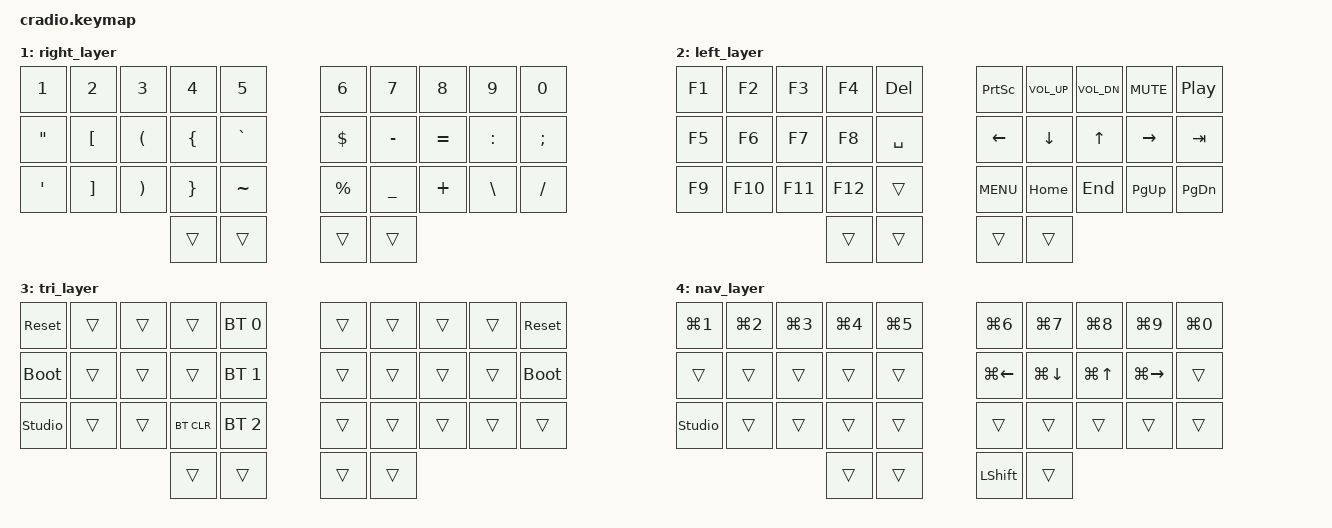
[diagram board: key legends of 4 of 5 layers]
// Copyright (c) 2022 The ZMK Contributors
// SPDX-License-Identifier: MIT

#include <behaviors.dtsi>
#include <dt-bindings/zmk/keys.h>
#include <dt-bindings/zmk/bt.h>

// Home row mods macro
#define HRML(k1,k2,k3,k4) &ht LGUI k1  &ht LALT k2  &ht LSHFT k3  &ht LCTRL k4
#define HRMR(k1,k2,k3,k4) &ht RCTRL k1  &ht RSHFT k2  &ht RALT k3  &ht RGUI k4

/ {
    behaviors {
        ht: hold_tap {
            compatible = "zmk,behavior-hold-tap";
            #binding-cells = <2>;
            flavor = "tap-preferred";
            tapping-term-ms = <220>;
            quick-tap-ms = <150>;
            require-prior-idle-ms = <100>;
            bindings = <&kp>, <&kp>;
        };
    };

    conditional_layers {
        compatible = "zmk,conditional-layers";
        tri_layer {
            if-layers = <1 2>;
            then-layer = <3>;
        };
    };

    keymap {
        compatible = "zmk,keymap";
        default_layer {
            bindings = <
        //╭──────────┬──────────┬──────────┬──────────┬──────────╮   ╭──────────┬──────────┬──────────┬──────────┬──────────╮
        //│  Q       │  W       │  E       │  R       │  T       │   │  Y       │  U       │  I       │  O       │  P       │
            &kp Q      &kp W      &kp E      &kp R      &kp T          &kp Y      &kp U      &kp I      &kp O      &kp P
        //├──────────┼──────────┼──────────┼──────────┼──────────┤   ├──────────┼──────────┼──────────┼──────────┼──────────┤
        //│  A       │  S       │  D       │  F       │  G       │   │  H       │  J       │  K       │  L       │ :        │
            HRML(A,        S,         D,         F)     &kp G          &kp H      HRMR(J,        K,         L,        SEMI)
        //├──────────┼──────────┼──────────┼──────────┼──────────┤   ├──────────┼──────────┼──────────┼──────────┼──────────┤
        //│  Z       │  X       │  C       │  V       │  B       │   │  N       │  M       │ , <      │ . >      │ / ?      │
            &kp Z      &kp X      &kp C      &kp V      &kp B          &kp N      &kp M      &kp COMMA  &kp DOT    &kp FSLH
        //╰──────────┴──────────┴──────────┼──────────┼──────────┤   ├──────────┼──────────┼──────────┴──────────┴──────────╯
                                           &lt 1 SPACE   &lt 4 ENTER   &lt 2 ESC  &lt 1 BSPC
        //                                 ╰──────────┴──────────╯   ╰──────────┴──────────╯
            >;
        };

        right_layer {
            bindings = <
        //╭──────────┬──────────┬──────────┬──────────┬──────────╮   ╭──────────┬──────────┬──────────┬──────────┬──────────╮
        //│ 1        │  2       │  3       │  4       │  5       │   │ 6        │ 7        │ 8        │ 9        │  0       │
            &kp N1     &kp N2     &kp N3     &kp N4     &kp N5         &kp N6     &kp N7      &kp N8    &kp N9     &kp N0
        //├──────────┼──────────┼──────────┼──────────┼──────────┤   ├──────────┼──────────┼──────────┼──────────┼──────────┤
        //│ "        │  [       │  (       │  {       │  `       │   │ $        │ -        │ =        │ :        │  ;       │
            &kp DQT    &kp LBKT   &kp LPAR   &kp LBRC   &kp GRAVE      &kp DLLR   &kp MINUS &kp EQUAL   &kp COLON   &kp SEMI
        //├──────────┼──────────┼──────────┼──────────┼──────────┤   ├──────────┼──────────┼──────────┼──────────┼──────────┤
        //│ '        │  ]       │  )       │  }       │  ~       │   │   %      │    _     │     +    │     \    │     /    │
           &kp SQT     &kp RBKT   &kp RPAR   &kp RBRC  &kp TILDE       &kp PRCNT  &kp UNDER  &kp PLUS   &kp BSLH   &kp FSLH
        //╰──────────┴──────────┴──────────┼──────────┼──────────┤   ├──────────┼──────────┼──────────┴──────────┴──────────╯
                                             &trans     &trans         &trans     &trans
        //                                 ╰──────────┴──────────╯   ╰──────────┴──────────╯
            >;
        };

        left_layer {
            bindings = <
        //╭──────────┬──────────┬──────────┬──────────┬──────────╮   ╭──────────┬──────────┬──────────┬──────────┬──────────╮
        //│    F1    │  F2      │  F3      │  F4      │   DEL    │   │  PSCRN   │  VOLUP   │ VOLDOWN  │  MUTE    │  PP      │
            &kp F1     &kp F2     &kp F3     &kp F4     &kp DEL        &kp PSCRN &kp C_VOL_UP &kp C_VOL_DN  &kp C_MUTE &kp C_PP
        //├──────────┼──────────┼──────────┼──────────┼──────────┤   ├──────────┼──────────┼──────────┼──────────┼──────────┤
        //│    F5    │  F6      │  F7      │  F8      │  SPACE   │   │  L       │  D       │  U       │  R       │  TAB     │
            &kp F5     &kp F6     &kp F7     &kp F8    &kp SPACE       &kp LEFT   &kp DOWN   &kp UP     &kp RIGHT   &kp TAB
        //├──────────┼──────────┼──────────┼──────────┼──────────┤   ├──────────┼──────────┼──────────┼──────────┼──────────┤
        //│    F9    │  F10     │  F11     │  F12     │          │   │  MENU    │  HOME    │  END     │  UP      │  DOWN    │
            &kp F9     &kp F10    &kp F11    &kp F12     &trans        &kp K_MENU   &kp HOME  &kp END   &kp PG_UP   &kp PG_DN
        //╰──────────┴──────────┴──────────┼──────────┼──────────┤   ├──────────┼──────────┼──────────┴──────────┴──────────╯
                                             &trans     &trans         &trans     &trans
        //                                 ╰──────────┴──────────╯   ╰──────────┴──────────╯
            >;
        };

        tri_layer {
            bindings = <
        //╭──────────┬──────────┬──────────┬──────────┬──────────╮   ╭──────────┬──────────┬──────────┬──────────┬──────────╮
        //│ RESET    │          │          │          │PROFILE 0 │   │          │          │          │          │  RESET   │
           &sys_reset  &trans     &trans     &trans    &bt BT_SEL 0    &trans     &trans     &trans     &trans    &sys_reset
        //├──────────┼──────────┼──────────┼──────────┼──────────┤   ├──────────┼──────────┼──────────┼──────────┼──────────┤
        //│BOOTLOADER│          │          │          │PROFILE 1 │   │          │          │          │          │BOOTLOADER│
          &bootloader  &trans     &trans     &trans    &bt BT_SEL 1    &trans     &trans     &trans     &trans    &bootloader
        //├──────────┼──────────┼──────────┼──────────┼──────────┤   ├──────────┼──────────┼──────────┼──────────┼──────────┤
        //│          │          │          │ CLEAR BT │PROFILE 2 │   │          │          │          │          │          │
        &studio_unlock &trans     &trans    &bt BT_CLR &bt BT_SEL 2    &trans     &trans     &trans     &trans     &trans
        //╰──────────┴──────────┴──────────┼──────────┼──────────┤   ├──────────┼──────────┼──────────┴──────────┴──────────╯
                                             &trans     &trans         &trans     &trans
        //                                 ╰──────────┴──────────╯   ╰──────────┴──────────╯
            >;
        };

        nav_layer {
            bindings = <
        //╭──────────┬──────────┬──────────┬──────────┬──────────╮   ╭──────────┬──────────┬──────────┬──────────┬──────────╮
        //│          │          │          │          │          │   │          │          │          │          │          │
           &kp LG(N1) &kp LG(N2) &kp LG(N3) &kp LG(N4) &kp LG(N5)     &kp LG(N6) &kp LG(N7) &kp LG(N8) &kp LG(N9) &kp LG(N0)
        //├──────────┼──────────┼──────────┼──────────┼──────────┤   ├──────────┼──────────┼──────────┼──────────┼──────────┤
        //│BOOTLOADER│          │          │          │PROFILE 1 │   │          │          │          │          │          │
             &trans     &trans     &trans     &trans    &trans       &kp LG(LEFT) &kp LG(DOWN) &kp LG(UP) &kp LG(RIGHT) &trans
        //├──────────┼──────────┼──────────┼──────────┼──────────┤   ├──────────┼──────────┼──────────┼──────────┼──────────┤
        //│          │          │          │          │          │   │          │          │          │          │          │
        &studio_unlock &trans     &trans      &trans     &trans         &trans     &trans     &trans     &trans     &trans
        //╰──────────┴──────────┴──────────┼──────────┼──────────┤   ├──────────┼──────────┼──────────┴──────────┴──────────╯
                                             &trans     &trans          &kp LSHFT  &trans
        //                                 ╰──────────┴──────────╯   ╰──────────┴──────────╯
            >;
        };
    };
};
